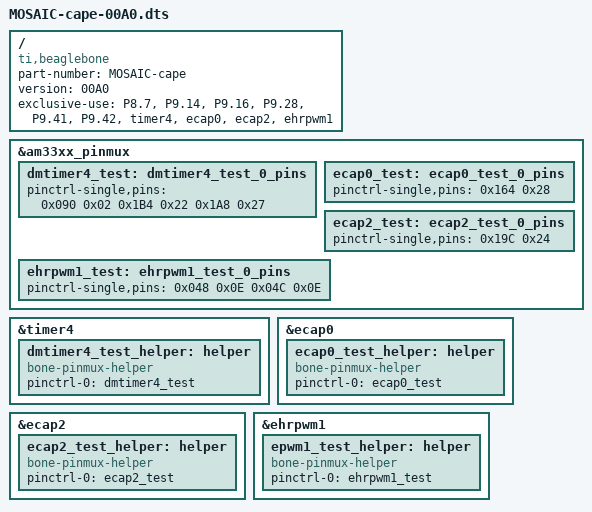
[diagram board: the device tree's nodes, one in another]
/dts-v1/;
/plugin/;

/{
	compatible = "ti,beaglebone", "ti,beaglebone-black";
	/* identification */
	part-number = "MOSAIC-cape";
	version = "00A0";

	exclusive-use = "P8.7", "P9.14", "P9.16", "P9.28", "P9.41", "P9.42", "timer4", "ecap0", "ecap2", "ehrpwm1";

	fragment@0 {
		target = <&am33xx_pinmux>;
		__overlay__ {
			dmtimer4_test: dmtimer4_test_0_pins {
				pinctrl-single,pins = <
					0x090 0x02 /* gpmc_advn_ale mode 2 (timer4) */
					0x1B4 0x22 /* xdma_event_intr1, mode 2 (tclkin), PD */
					0x1A8 0x27 /* mcasp0_axr1, mode 7 (gpio3_20), PD (shares P9.41 with tclkin) */
				>;
			};
			ecap0_test: ecap0_test_0_pins {
				pinctrl-single,pins = <
					0x164 0x28 /* eCAP0_in_PWM0_out, mode 0, input */
				>;
			};
			ecap2_test: ecap2_test_0_pins {
				pinctrl-single,pins = <
					0x19C 0x24 /* mcasp0_ahclkr, mode 4 (eCAP2_in_PWM2_out), input, PD */
				>;
			};
			ehrpwm1_test: ehrpwm1_test_0_pins {
				pinctrl-single,pins = <
					0x048 0x0E /* gpmc_a2, mode 6 (ehrpwm1a) */
					0x04C 0x0E /* gpmc_a3, mode 6 (ehrpwm1b) */
				>;
			};


		};
	};

    fragment@1 {
        target = <&timer4>;
        __overlay__ {
            dmtimer4_test_helper: helper {
                compatible = "bone-pinmux-helper";
                pinctrl-names = "default";
                pinctrl-0 = <&dmtimer4_test>;
                status = "okay";
            };
        };
    };

    fragment@2 {
        target = <&ecap0>;
        __overlay__ {
            ecap0_test_helper: helper {
                compatible = "bone-pinmux-helper";
                pinctrl-names = "default";
                pinctrl-0 = <&ecap0_test>;
                status = "okay";
            };
        };
    };

    fragment@3 {
        target = <&ecap2>;
        __overlay__ {
            ecap2_test_helper: helper {
                compatible = "bone-pinmux-helper";
                pinctrl-names = "default";
                pinctrl-0 = <&ecap2_test>;
                status = "okay";
            };
        };
    };

    fragment@4 {
        target = <&ehrpwm1>;
        __overlay__ {
            epwm1_test_helper: helper {
                compatible = "bone-pinmux-helper";
                pinctrl-names = "default";
                pinctrl-0 = <&ehrpwm1_test>;
                status = "okay";
            };
        };
    };


};

